# ATSAM4LS8B register map
Vendor: Atmel Corporation; Series: SAM4L; File version: A
CPU: CM4 r0p1, little endian, MPU, no FPU, 4 interrupt priority bits
Registers are 32-bit, write-only, reset 0x0 unless marked. A register's access mark holds for its fields unless they carry their own. Offsets are from the block's base; [hi:lo] are bit positions; {n}, {i} and the like mark numbered series; 'fields as' and 'values as' point back to an identical list.

## SCIF — System Control Interface
Base 0x400E0800; register names take the prefix SCIF_
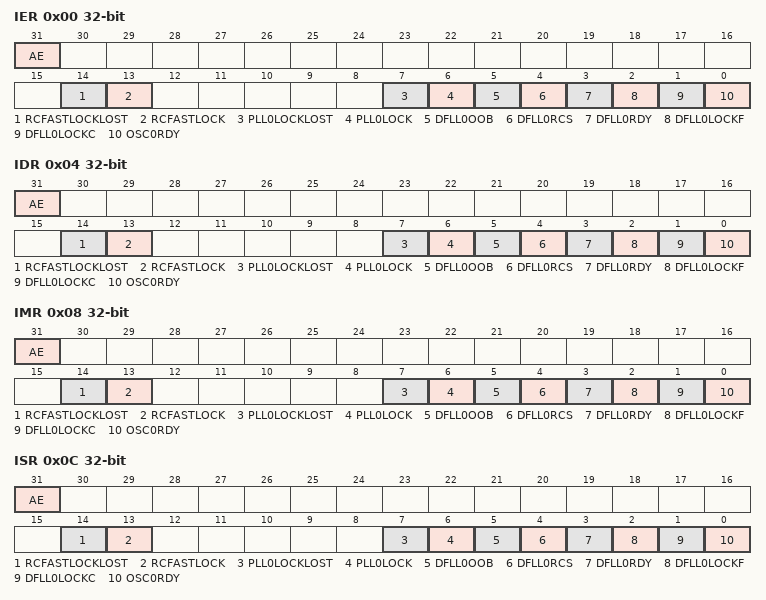
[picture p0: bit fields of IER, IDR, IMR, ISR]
0x00 IER — Interrupt Enable Register
  [31] AE — Access Error
  [14] RCFASTLOCKLOST
  [13] RCFASTLOCK
  [7] PLL0LOCKLOST
  [6] PLL0LOCK
  [5] DFLL0OOB — DFLL0 Out Of Bounds
  [4] DFLL0RCS — DFLL0 Reference Clock Stopped
  [3] DFLL0RDY — DFLL0 Ready
  [2] DFLL0LOCKF — DFLL0 Lock Fine
  [1] DFLL0LOCKC — DFLL0 Lock Coarse
  [0] OSC0RDY — OSC0 Ready
0x04 IDR — Interrupt Disable Register
  fields as IER
0x08 IMR ro — Interrupt Mask Register
  fields as IER
0x0C ISR ro — Interrupt Status Register
  fields as IER
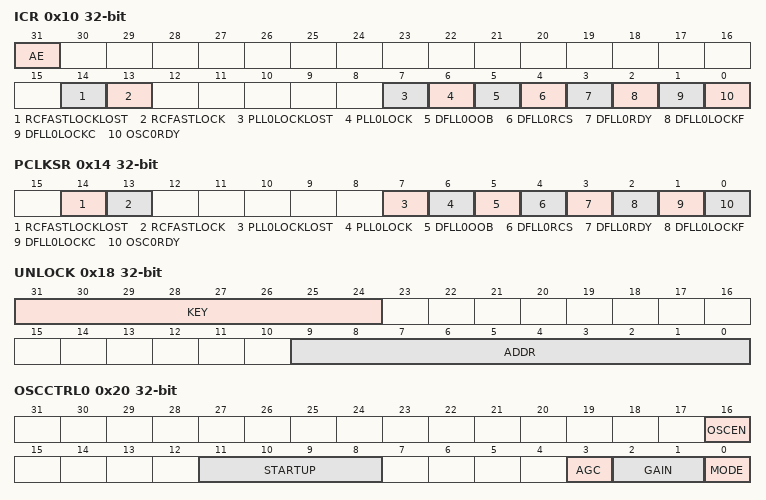
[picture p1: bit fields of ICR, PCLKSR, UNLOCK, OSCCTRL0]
0x10 ICR — Interrupt Clear Register
  fields as IER
0x14 PCLKSR ro — Power and Clocks Status Register
  [14] RCFASTLOCKLOST — RCFAST lock lost value
  [13] RCFASTLOCK — RCFAST Locked on Accurate value
  [7] PLL0LOCKLOST — PLL0 lock lost value
  [6] PLL0LOCK — PLL0 Locked on Accurate value
  [5] DFLL0OOB — DFLL0 Track Out Of Bounds
  [4] DFLL0RCS — DFLL0 Reference Clock Stopped
  [3] DFLL0RDY — DFLL0 Synchronization Ready
  [2] DFLL0LOCKF — DFLL0 Locked on Fine Value
  [1] DFLL0LOCKC — DFLL0 Locked on Coarse Value
  [0] OSC0RDY — OSC0 Ready
0x18 UNLOCK
  [31:24] KEY — Unlock Key
  [9:0] ADDR — Unlock Address
0x1C CSCR rw — Chip Specific Configuration Register
0x20 OSCCTRL0 rw — Oscillator Control Register
  [16] OSCEN — Oscillator Enable
  [11:8] STARTUP — Oscillator Start-up Time
  [3] AGC — Automatic Gain Control
  [2:1] GAIN
  [0] MODE — Oscillator Mode
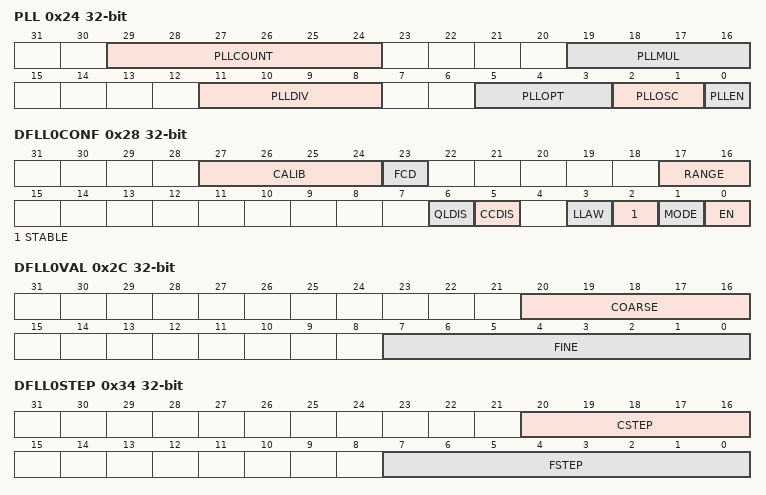
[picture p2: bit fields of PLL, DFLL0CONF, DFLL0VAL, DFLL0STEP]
0x24 PLL rw — PLL0 Control Register
  [29:24] PLLCOUNT
  [19:16] PLLMUL — PLL Multiply Factor
  [11:8] PLLDIV — PLL Division Factor
  [5:3] PLLOPT — PLL Option
  [2:1] PLLOSC — PLL Oscillator Select
  [0] PLLEN — PLL Enable
0x28 DFLL0CONF rw — DFLL0 Config Register
  [27:24] CALIB — Calibration Value
  [23] FCD — Fuse Calibration Done
  [17:16] RANGE — Range Value
  [6] QLDIS — Quick Lock Disable
  [5] CCDIS — Chill Cycle Disable
  [3] LLAW — Lose Lock After Wake
  [2] STABLE — Stable DFLL Frequency
  [1] MODE — Mode Selection
  [0] EN — Enable
0x2C DFLL0VAL rw — DFLL Value Register
  [20:16] COARSE — Coarse Value
  [7:0] FINE — Fine Value
0x30 DFLL0MUL rw — DFLL0 Multiplier Register
  [15:0] MUL — DFLL Multiply Factor
0x34 DFLL0STEP rw
  [20:16] CSTEP — Coarse Maximum Step
  [7:0] FSTEP — Fine Maximum Step
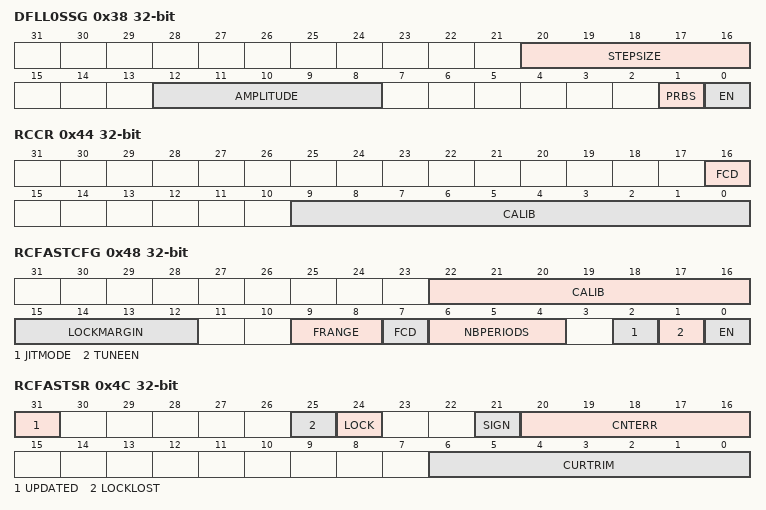
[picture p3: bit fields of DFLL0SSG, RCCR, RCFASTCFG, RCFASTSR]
0x38 DFLL0SSG rw — DFLL0 Spread Spectrum Generator Control Register
  [20:16] STEPSIZE wo — SSG Step Size
  [12:8] AMPLITUDE wo — SSG Amplitude
  [1] PRBS wo — Pseudo Random Bit Sequence
  [0] EN wo — Enable
0x3C DFLL0RATIO ro — DFLL0 Ratio Registe
  [15:0] RATIODIFF — Multiplication Ratio Difference
0x40 DFLL0SYNC — DFLL0 Synchronization Register
  [0] SYNC — Synchronization
0x44 RCCR rw — System RC Oscillator Calibration Register
  [16] FCD — Flash Calibration Done
  [9:0] CALIB — Calibration Value
0x48 RCFASTCFG rw — 4/8/12 MHz RC Oscillator Configuration Register
  [22:16] CALIB — Oscillator Calibration Value
  [15:12] LOCKMARGIN — Accepted Count Error for Lock
  [9:8] FRANGE — Frequency Range
  [7] FCD — RCFAST Fuse Calibration Done
  [6:4] NBPERIODS — Number of 32kHz Periods
  [2] JITMODE — Jitter Mode
  [1] TUNEEN — Tuner Enable
  [0] EN — Oscillator Enable
0x4C RCFASTSR rw — 4/8/12 MHz RC Oscillator Status Register
  [31] UPDATED — Current Trim Value Updated
  [25] LOCKLOST
  [24] LOCK
  [21] SIGN — Sign of Current Count Error
  [20:16] CNTERR — Current Count Error
  [6:0] CURTRIM — Current Trim Value
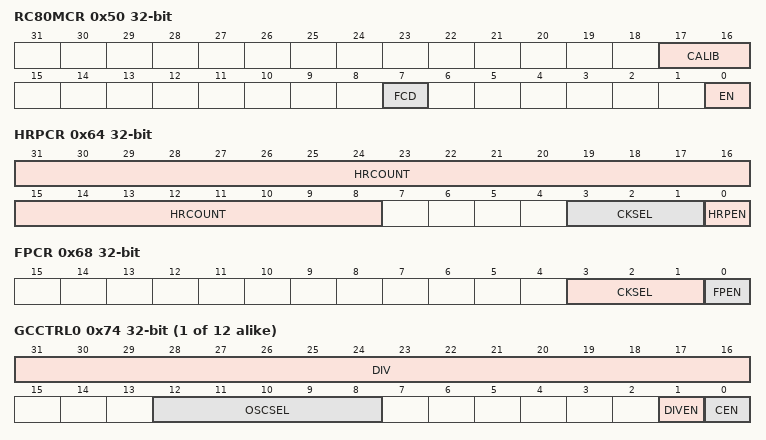
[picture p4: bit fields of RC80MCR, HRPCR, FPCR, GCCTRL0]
0x50 RC80MCR rw — 80 MHz RC Oscillator Register
  [17:16] CALIB — Calibration Value
  [7] FCD — Flash Calibration Done
  [0] EN — Enable
0x64 HRPCR rw — High Resolution Prescaler Control Register
  [31:8] HRCOUNT — High Resolution Counter
  [3:1] CKSEL — Clock Input Selection
  [0] HRPEN — High Resolution Prescaler Enable
0x68 FPCR rw — Fractional Prescaler Control Register
  [3:1] CKSEL — Clock Input Selection
  [0] FPEN — High Resolution Prescaler Enable
0x6C FPMUL rw — Fractional Prescaler Multiplier Register
  [15:0] FPMUL — Fractional Prescaler Multiplication Factor
0x70 FPDIV rw — Fractional Prescaler DIVIDER Register
  [15:0] FPDIV — Fractional Prescaler Division Factor
{0x74+4i} GCCTRL{i} (i=0..11) rw — Generic Clock Control
  [31:16] DIV — Division Factor
  [12:8] OSCSEL — Clock Select
  [1] DIVEN — Divide Enable
  [0] CEN — Clock Enable
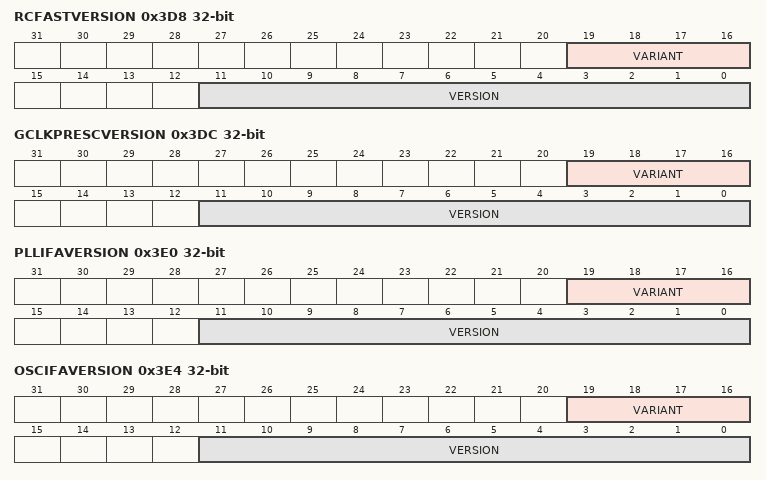
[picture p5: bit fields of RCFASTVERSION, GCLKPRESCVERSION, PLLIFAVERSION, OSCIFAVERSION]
0x3D8 RCFASTVERSION ro — 4/8/12 MHz RC Oscillator Version Register
  [19:16] VARIANT — Variant number
  [11:0] VERSION — Version number
0x3DC GCLKPRESCVERSION ro — Generic Clock Prescaler Version Register
  [19:16] VARIANT — Variant number
  [11:0] VERSION — Version number
0x3E0 PLLIFAVERSION ro — PLL Version Register
  [19:16] VARIANT — Variant nubmer
  [11:0] VERSION — Version number
0x3E4 OSCIFAVERSION ro — Oscillator 0 Version Register
  [19:16] VARIANT — Variant nubmer
  [11:0] VERSION — Version number
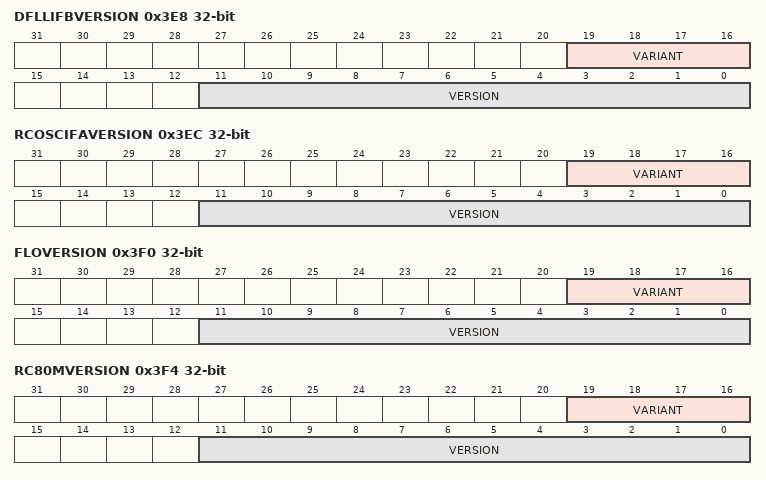
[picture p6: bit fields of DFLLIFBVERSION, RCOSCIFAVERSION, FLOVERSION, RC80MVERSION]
0x3E8 DFLLIFBVERSION ro — DFLL Version Register
  [19:16] VARIANT — Variant number
  [11:0] VERSION — Version number
0x3EC RCOSCIFAVERSION ro — System RC Oscillator Version Register
  [19:16] VARIANT — Variant number
  [11:0] VERSION — Version number
0x3F0 FLOVERSION ro — Frequency Locked Oscillator Version Register
  [19:16] VARIANT — Variant number
  [11:0] VERSION — Version number
0x3F4 RC80MVERSION ro — 80MHz RC Oscillator Version Register
  [19:16] VARIANT — Variant number
  [11:0] VERSION — Version number
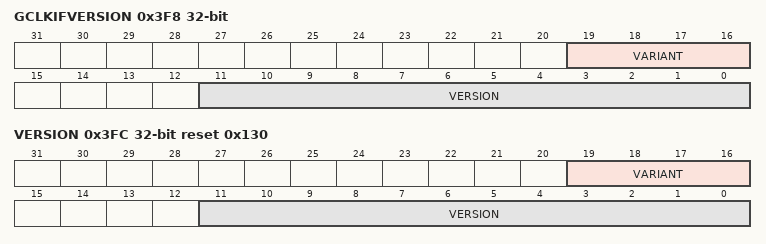
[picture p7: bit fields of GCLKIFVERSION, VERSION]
0x3F8 GCLKIFVERSION ro — Generic Clock Version Register
  [19:16] VARIANT — Variant number
  [11:0] VERSION — Version number
0x3FC VERSION ro reset 0x130 — SCIF Version Register
  [19:16] VARIANT — Variant number
  [11:0] VERSION — Version number

## Notices in the file
Atmel Microcontroller Software Support
Copyright (c) 2014, Atmel Corporation
All rights reserved.
Redistribution and use in source and binary forms, with or without
modification, are permitted provided that the following condition is met:
- Redistributions of source code must retain the above copyright notice,
this list of conditions and the disclaimer below.
Atmel's name may not be used to endorse or promote products derived from
this software without specific prior written permission.
DISCLAIMER: THIS SOFTWARE IS PROVIDED BY ATMEL "AS IS" AND ANY EXPRESS OR
IMPLIED WARRANTIES, INCLUDING, BUT NOT LIMITED TO, THE IMPLIED WARRANTIES OF
MERCHANTABILITY, FITNESS FOR A PARTICULAR PURPOSE AND NON-INFRINGEMENT ARE
DISCLAIMED. IN NO EVENT SHALL ATMEL BE LIABLE FOR ANY DIRECT, INDIRECT,
INCIDENTAL, SPECIAL, EXEMPLARY, OR CONSEQUENTIAL DAMAGES (INCLUDING, BUT NOT
LIMITED TO, PROCUREMENT OF SUBSTITUTE GOODS OR SERVICES; LOSS OF USE, DATA,
OR PROFITS; OR BUSINESS INTERRUPTION) HOWEVER CAUSED AND ON ANY THEORY OF
LIABILITY, WHETHER IN CONTRACT, STRICT LIABILITY, OR TORT (INCLUDING
NEGLIGENCE OR OTHERWISE) ARISING IN ANY WAY OUT OF THE USE OF THIS SOFTWARE,
EVEN IF ADVISED OF THE POSSIBILITY OF SUCH DAMAGE.
